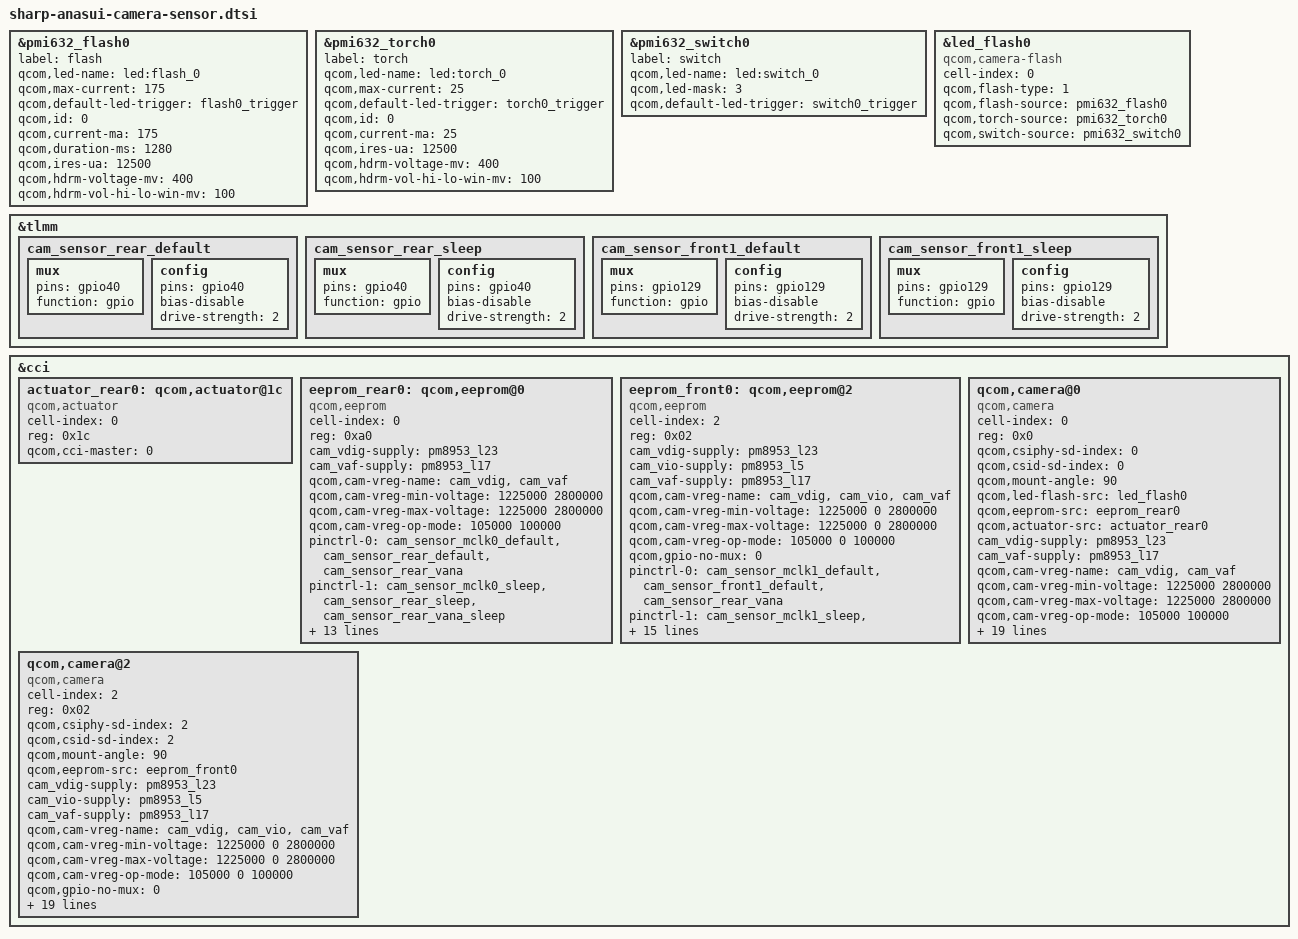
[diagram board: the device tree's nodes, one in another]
/*
 * Copyright (c) 2016, The Linux Foundation. All rights reserved.
 *
 * This program is free software; you can redistribute it and/or modify
 * it under the terms of the GNU General Public License version 2 and
 * only version 2 as published by the Free Software Foundation.
 *
 * This program is distributed in the hope that it will be useful,
 * but WITHOUT ANY WARRANTY; without even the implied warranty of
 * MERCHANTABILITY or FITNESS FOR A PARTICULAR PURPOSE.  See the
 * GNU General Public License for more details.
 */

&pmi632_flash0 {
	label = "flash";
	qcom,led-name = "led:flash_0";
	qcom,max-current = <175>;
	qcom,default-led-trigger = "flash0_trigger";
	qcom,id = <0>;
	qcom,current-ma = <175>;
	qcom,duration-ms = <1280>;
	qcom,ires-ua = <12500>;
	qcom,hdrm-voltage-mv = <400>;
	qcom,hdrm-vol-hi-lo-win-mv = <100>;
};

&pmi632_torch0 {
	label = "torch";
	qcom,led-name = "led:torch_0";
	qcom,max-current = <25>;
	qcom,default-led-trigger = "torch0_trigger";
	qcom,id = <0>;
	qcom,current-ma = <25>;
	qcom,ires-ua = <12500>;
	qcom,hdrm-voltage-mv = <400>;
	qcom,hdrm-vol-hi-lo-win-mv = <100>;
};

&pmi632_switch0 {
	label = "switch";
	qcom,led-name = "led:switch_0";
	qcom,led-mask = <3>;
	qcom,default-led-trigger = "switch0_trigger";
};

&led_flash0 {
	cell-index = <0>;
	compatible = "qcom,camera-flash";
	qcom,flash-type = <1>;
	qcom,flash-source = <&pmi632_flash0>;
	qcom,torch-source = <&pmi632_torch0>;
	qcom,switch-source = <&pmi632_switch0>;
};

&tlmm {
	/delete-node/ cam_sensor_rear_default;
	/delete-node/ cam_sensor_rear_sleep;
	/delete-node/ cam_sensor_front1_default;
	/delete-node/ cam_sensor_front1_sleep;

		cam_sensor_rear_default: cam_sensor_rear_default {
			/* RESET, STANDBY */
			mux {
				pins = "gpio40";
				function = "gpio";
			};

			config {
				pins = "gpio40";
				bias-disable; /* No PULL */
				drive-strength = <2>; /* 2 MA */
			};
		};

		cam_sensor_rear_sleep: cam_sensor_rear_sleep {
			/* RESET, STANDBY */
			mux {
				pins = "gpio40";
				function = "gpio";
			};

			config {
				pins = "gpio40";
				bias-disable; /* No PULL */
				drive-strength = <2>; /* 2 MA */
			};
		};

		cam_sensor_front1_default: cam_sensor_front1_default {
			/* RESET, STANDBY */
			mux {
				pins = "gpio129";
				function = "gpio";
			};

			config {
				pins = "gpio129";
				bias-disable; /* No PULL */
				drive-strength = <2>; /* 2 MA */
			};
		};

		cam_sensor_front1_sleep: cam_sensor_front1_sleep {
			/* RESET, STANDBY */
			mux {
				pins = "gpio129";
				function = "gpio";
			};

			config {
				pins = "gpio129";
				bias-disable; /* No PULL */
				drive-strength = <2>; /* 2 MA */
			};
		};


};


/delete-node/ &camera1;

&cci {
	/delete-node/ qcom,actuator@0;
	/delete-node/ qcom,actuator@1;
	/delete-node/ qcom,eeprom@0;
	/delete-node/ qcom,eeprom@1;
	/delete-node/ qcom,eeprom@2;
	/delete-node/ qcom,camera@0;
	/delete-node/ qcom,camera@2;

	actuator_rear0: qcom,actuator@1c {
		cell-index = <0>;
		reg = <0x1c>;
		compatible = "qcom,actuator";
		qcom,cci-master = <0>;
	};

	eeprom_rear0: qcom,eeprom@0 {
		cell-index = <0>;
		reg = <0xa0>;
		compatible = "qcom,eeprom";
		cam_vdig-supply = <&pm8953_l23>;
		cam_vaf-supply = <&pm8953_l17>;
		qcom,cam-vreg-name = "cam_vdig", "cam_vaf";
		qcom,cam-vreg-min-voltage = <1225000 2800000>;
		qcom,cam-vreg-max-voltage = <1225000 2800000>;
		qcom,cam-vreg-op-mode = <105000 100000>;
		pinctrl-names = "cam_default", "cam_suspend";
		pinctrl-0 = <&cam_sensor_mclk0_default
				&cam_sensor_rear_default
				&cam_sensor_rear_vana>;
		pinctrl-1 = <&cam_sensor_mclk0_sleep &cam_sensor_rear_sleep
				&cam_sensor_rear_vana_sleep>;
		gpios = <&tlmm 26 0>,
			<&tlmm 40 0>,
			<&tlmm 134 0>;
		qcom,gpio-reset = <1>;
		qcom,gpio-vana = <2>;
		qcom,gpio-req-tbl-num = <0 1 2>;
		qcom,gpio-req-tbl-flags = <1 0 0>;
		qcom,gpio-req-tbl-label = "CAMIF_MCLK0",
			"CAM_RESET0",
			"CAM_VANA0";
		qcom,sensor-position = <0>;
		qcom,sensor-mode = <0>;
		qcom,cci-master = <0>;
		status = "ok";
		clocks = <&clock_gcc clk_mclk0_clk_src>,
				<&clock_gcc clk_gcc_camss_mclk0_clk>;
		clock-names = "cam_src_clk", "cam_clk";
		qcom,clock-rates = <24000000 0>;
	};

	eeprom_front0: qcom,eeprom@2 {
		cell-index = <2>;
		reg = <0x02>;
		compatible = "qcom,eeprom";
		cam_vdig-supply = <&pm8953_l23>;
		cam_vio-supply = <&pm8953_l5>;
		cam_vaf-supply = <&pm8953_l17>;
		qcom,cam-vreg-name = "cam_vdig", "cam_vio", "cam_vaf";
		qcom,cam-vreg-min-voltage = <1225000 0 2800000>;
		qcom,cam-vreg-max-voltage = <1225000 0 2800000>;
		qcom,cam-vreg-op-mode = <105000 0 100000>;
		qcom,gpio-no-mux = <0>;
		pinctrl-names = "cam_default", "cam_suspend";
		pinctrl-0 = <&cam_sensor_mclk1_default
				&cam_sensor_front1_default &cam_sensor_rear_vana>;
		pinctrl-1 = <&cam_sensor_mclk1_sleep
				&cam_sensor_front1_sleep &cam_sensor_rear_vana_sleep>;
		gpios = <&tlmm 27 0>,
			<&tlmm 129 0>,
			<&tlmm 134 0>;
		qcom,gpio-reset = <1>;
		qcom,gpio-vana = <2>;
		qcom,gpio-req-tbl-num = <0 1 2>;
		qcom,gpio-req-tbl-flags = <1 0 0>;
		qcom,gpio-req-tbl-label = "CAMIF_MCLK2",
					  "CAM_RESET2",
					  "CAM_VANA2";
		qcom,sensor-position = <1>;
		qcom,sensor-mode = <0>;
		qcom,cci-master = <1>;
		status = "ok";
		clocks = <&clock_gcc clk_mclk1_clk_src>,
			<&clock_gcc clk_gcc_camss_mclk1_clk>;
		clock-names = "cam_src_clk", "cam_clk";
		qcom,clock-rates = <24000000 0>;
	};

	qcom,camera@0 {
		cell-index = <0>;
		compatible = "qcom,camera";
		reg = <0x0>;
		qcom,csiphy-sd-index = <0>;
		qcom,csid-sd-index = <0>;
		qcom,mount-angle = <90>;
		qcom,led-flash-src = <&led_flash0>;
		qcom,eeprom-src = <&eeprom_rear0>;
		qcom,actuator-src = <&actuator_rear0>;
		cam_vdig-supply = <&pm8953_l23>;
		cam_vaf-supply = <&pm8953_l17>;
		qcom,cam-vreg-name = "cam_vdig", "cam_vaf";
		qcom,cam-vreg-min-voltage = <1225000 2800000>;
		qcom,cam-vreg-max-voltage = <1225000 2800000>;
		qcom,cam-vreg-op-mode = <105000 100000>;
		pinctrl-names = "cam_default", "cam_suspend";
		pinctrl-0 = <&cam_sensor_mclk0_default
				&cam_sensor_rear_default
				&cam_sensor_rear_vana>;
		pinctrl-1 = <&cam_sensor_mclk0_sleep &cam_sensor_rear_sleep
				&cam_sensor_rear_vana_sleep>;
		gpios = <&tlmm 26 0>,
			<&tlmm 40 0>,
			<&tlmm 134 0>;
		qcom,gpio-reset = <1>;
		qcom,gpio-vana = <2>;
		qcom,gpio-req-tbl-num = <0 1 2>;
		qcom,gpio-req-tbl-flags = <1 0 0>;
		qcom,gpio-req-tbl-label = "CAMIF_MCLK0",
			"CAM_RESET0",
			"CAM_VANA0";
		qcom,sensor-position = <0>;
		qcom,sensor-mode = <0>;
		qcom,cci-master = <0>;
		status = "ok";
		clocks = <&clock_gcc clk_mclk0_clk_src>,
				<&clock_gcc clk_gcc_camss_mclk0_clk>;
		clock-names = "cam_src_clk", "cam_clk";
		qcom,clock-rates = <24000000 0>;
	};

	qcom,camera@2 {
		cell-index = <2>;
		compatible = "qcom,camera";
		reg = <0x02>;
		qcom,csiphy-sd-index = <2>;
		qcom,csid-sd-index = <2>;
		qcom,mount-angle = <90>;
		qcom,eeprom-src = <&eeprom_front0>;
//		qcom,actuator-src = <0>;
		cam_vdig-supply = <&pm8953_l23>;
		cam_vio-supply = <&pm8953_l5>;
		cam_vaf-supply = <&pm8953_l17>;
		qcom,cam-vreg-name = "cam_vdig", "cam_vio", "cam_vaf";
		qcom,cam-vreg-min-voltage = <1225000 0 2800000>;
		qcom,cam-vreg-max-voltage = <1225000 0 2800000>;
		qcom,cam-vreg-op-mode = <105000 0 100000>;
		qcom,gpio-no-mux = <0>;
		pinctrl-names = "cam_default", "cam_suspend";
		pinctrl-0 = <&cam_sensor_mclk1_default
				&cam_sensor_front1_default &cam_sensor_rear_vana>;
		pinctrl-1 = <&cam_sensor_mclk1_sleep
				&cam_sensor_front1_sleep &cam_sensor_rear_vana_sleep>;
		gpios = <&tlmm 27 0>,
			<&tlmm 129 0>,
			<&tlmm 134 0>;
		qcom,gpio-reset = <1>;
		qcom,gpio-vana = <2>;
		qcom,gpio-req-tbl-num = <0 1 2>;
		qcom,gpio-req-tbl-flags = <1 0 0>;
		qcom,gpio-req-tbl-label = "CAMIF_MCLK2",
			"CAM_RESET2",
			"CAM_VANA2";
		qcom,sensor-position = <1>;
		qcom,sensor-mode = <0>;
		qcom,cci-master = <1>;
		status = "ok";
		clocks = <&clock_gcc clk_mclk1_clk_src>,
			<&clock_gcc clk_gcc_camss_mclk1_clk>;
		clock-names = "cam_src_clk", "cam_clk";
		qcom,clock-rates = <24000000 0>;
	};
};

